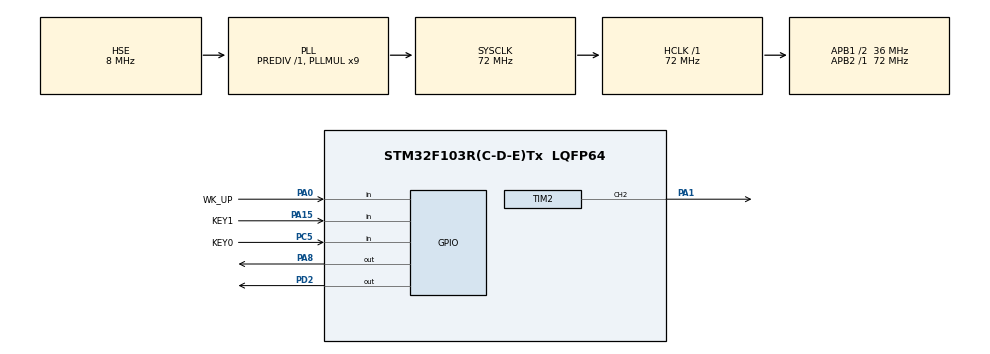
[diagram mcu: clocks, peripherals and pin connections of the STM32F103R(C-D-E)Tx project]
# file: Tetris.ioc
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Mcu.Family=STM32F1
Mcu.Name=STM32F103R(C-D-E)Tx
Mcu.Package=LQFP64
NVIC.PriorityGroup=NVIC_PRIORITYGROUP_4
PA0-WKUP.GPIO_Label=WK_UP
PA0-WKUP.GPIO_PuPd=GPIO_PULLDOWN
PA0-WKUP.Signal=GPIO_Input
PA1.GPIO_ModeDefaultPP=GPIO_MODE_AF_PP
PA1.GPIO_Speed=GPIO_SPEED_FREQ_LOW
PA1.Signal=S_TIM2_CH2
PA13.Mode=Serial_Wire
PA13.Signal=SYS_JTMS-SWDIO
PA14.Mode=Serial_Wire
PA14.Signal=SYS_JTCK-SWCLK
PA15.GPIO_Label=KEY1
PA15.GPIO_PuPd=GPIO_PULLUP
PA15.Signal=GPIO_Input
PA8.Signal=GPIO_Output
PC5.GPIO_Label=KEY0
PC5.GPIO_PuPd=GPIO_PULLUP
PC5.Signal=GPIO_Input
PD0-OSC_IN.Mode=HSE-External-Oscillator
PD0-OSC_IN.Signal=RCC_OSC_IN
PD1-OSC_OUT.Mode=HSE-External-Oscillator
PD1-OSC_OUT.Signal=RCC_OSC_OUT
PD2.Signal=GPIO_Output
ProjectManager.HeapSize=0x200
ProjectManager.StackSize=0x400
ProjectManager.TargetToolchain=STM32CubeIDE
RCC.AHBFreq_Value=72000000
RCC.APB1CLKDivider=RCC_HCLK_DIV2
RCC.APB1Freq_Value=36000000
RCC.APB1TimFreq_Value=72000000
RCC.APB2Freq_Value=72000000
RCC.APB2TimFreq_Value=72000000
RCC.HCLKFreq_Value=72000000
RCC.PLLMUL=RCC_PLL_MUL9
RCC.PLLSourceVirtual=RCC_PLLSOURCE_HSE
RCC.SYSCLKFreq_VALUE=72000000
RCC.SYSCLKSource=RCC_SYSCLKSOURCE_PLLCLK
RCC.USBFreq_Value=72000000
SH.S_TIM2_CH2.0=TIM2_CH2,PWM Generation2 CH2
TIM2.Channel-PWM\ Generation2\ CH2=TIM_CHANNEL_2
TIM2.Period=999
TIM2.Prescaler=71
board=custom

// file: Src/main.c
/* USER CODE BEGIN Header */
/**
  ******************************************************************************
  * @file           : main.c
  * @brief          : Main program body
  ******************************************************************************
  * @attention
  *
  * <h2><center>&copy; Copyright (c) 2019 STMicroelectronics.
  * All rights reserved.</center></h2>
  *
  * This software component is licensed by ST under BSD 3-Clause license,
  * the "License"; You may not use this file except in compliance with the
  * License. You may obtain a copy of the License at:
  *                        opensource.org/licenses/BSD-3-Clause
  *
  ******************************************************************************
  */
/* USER CODE END Header */

#include "main.h"

/* USER CODE BEGIN Includes */
#include "lcd.h"
#include "string.h"
#include "stdio.h"
#include "ui.h"

/* USER CODE END Includes */

TIM_HandleTypeDef htim2;

/* USER CODE BEGIN PV */
extern uint32_t uwTick;
extern const unsigned char JPGBUFF[];
// extern unsigned char JPGBUFF1[];
// extern unsigned char JPGBUFF2[];
// extern unsigned char JPGBUFF3[];
// extern unsigned char JPGBUFF4[];
/* USER CODE END PV */

void SystemClock_Config(void);
static void MX_GPIO_Init(void);
static void MX_TIM2_Init(void);

int main(void)
{

  /* MCU Configuration--------------------------------------------------------*/

  /* Reset of all peripherals, Initializes the Flash interface and the Systick. */
  HAL_Init();

  /* USER CODE BEGIN Init */
  LCD_Init();
  /* USER CODE END Init */

  /* Configure the system clock */
  SystemClock_Config();

  /* Initialize all configured peripherals */
  MX_GPIO_Init();
  MX_TIM2_Init();
  /* USER CODE BEGIN 2 */

  // LCD_Clear(WHITE);
  // POINT_COLOR = RED;
  // LCD_ShowString(30, 60, 200, 24, 24, (uint8_t*) "Tetris Welcome!");
  // POINT_COLOR = BLACK;
	// LCD_ShowString(30, 160, 200, 16, 16, (uint8_t*) "Press any key to start.");
  // // play_music();
  // while(1){
  //   HAL_Delay(21);
  //   if (HAL_GPIO_ReadPin(KEY1_GPIO_Port, KEY1_Pin) != GPIO_PIN_SET) {break;}
  //   if (HAL_GPIO_ReadPin(KEY0_GPIO_Port, KEY0_Pin) != GPIO_PIN_SET) {break;}
  //   if (HAL_GPIO_ReadPin(WK_UP_GPIO_Port, WK_UP_Pin) != GPIO_PIN_RESET) {break;}
  // }
  // LCD_Clear(WHITE);
  // game_reset();
  /* USER CODE END 2 */

  /* Infinite loop */
  while (1)
  {

    /* USER CODE BEGIN 3 */
	  POINT_COLOR=0xf100;//画笔颜色
    LCD_ShowString(30, 100, 240, 24, 24, "This is a test for JPG Decode!");
    HAL_Delay(1000);
    while (1)
    {
		LoadJpegFile(JPGBUFF);
    HAL_Delay(1800);HAL_Delay(1800);
		// LoadJpegFile(JPGBUFF1);
		// HAL_Delay(1800);HAL_Delay(1800);
		// LoadJpegFile(JPGBUFF2);
		// HAL_Delay(1800);HAL_Delay(1800);
		// LoadJpegFile(JPGBUFF3);
		// HAL_Delay(1800);HAL_Delay(1800);
		//TFT_CLEAR(0,0,240,320);//清屏
		// LoadJpegFile(JPGBUFF4);
		// HAL_Delay(1800);HAL_Delay(1800);
    }

    // if(uwTick - button_task_stamp >= button_update_interval){
		// 	button_task_stamp = uwTick;
		// 	button_update();
		// }
		// if(uwTick - fall_task_stamp >= fall_down_interval){
		// 	fall_task_stamp = uwTick;
		// 	grid_fall_down();
		// }

  }
  /* USER CODE END 3 */
}

void SystemClock_Config(void)
{
  RCC_OscInitTypeDef RCC_OscInitStruct = {0};
  RCC_ClkInitTypeDef RCC_ClkInitStruct = {0};

  /** Initializes the CPU, AHB and APB busses clocks
  */
  RCC_OscInitStruct.OscillatorType = RCC_OSCILLATORTYPE_HSE;
  RCC_OscInitStruct.HSEState = RCC_HSE_ON;
  RCC_OscInitStruct.HSEPredivValue = RCC_HSE_PREDIV_DIV1;
  RCC_OscInitStruct.HSIState = RCC_HSI_ON;
  RCC_OscInitStruct.PLL.PLLState = RCC_PLL_ON;
  RCC_OscInitStruct.PLL.PLLSource = RCC_PLLSOURCE_HSE;
  RCC_OscInitStruct.PLL.PLLMUL = RCC_PLL_MUL9;
  if (HAL_RCC_OscConfig(&RCC_OscInitStruct) != HAL_OK)
  {
    Error_Handler();
  }
  /** Initializes the CPU, AHB and APB busses clocks
  */
  RCC_ClkInitStruct.ClockType = RCC_CLOCKTYPE_HCLK|RCC_CLOCKTYPE_SYSCLK
                              |RCC_CLOCKTYPE_PCLK1|RCC_CLOCKTYPE_PCLK2;
  RCC_ClkInitStruct.SYSCLKSource = RCC_SYSCLKSOURCE_PLLCLK;
  RCC_ClkInitStruct.AHBCLKDivider = RCC_SYSCLK_DIV1;
  RCC_ClkInitStruct.APB1CLKDivider = RCC_HCLK_DIV2;
  RCC_ClkInitStruct.APB2CLKDivider = RCC_HCLK_DIV1;

  if (HAL_RCC_ClockConfig(&RCC_ClkInitStruct, FLASH_LATENCY_2) != HAL_OK)
  {
    Error_Handler();
  }
}

static void MX_TIM2_Init(void)
{

  TIM_MasterConfigTypeDef sMasterConfig = {0};
  TIM_OC_InitTypeDef sConfigOC = {0};

  htim2.Instance = TIM2;
  htim2.Init.Prescaler = 71;
  htim2.Init.CounterMode = TIM_COUNTERMODE_UP;
  htim2.Init.Period = 999;
  htim2.Init.ClockDivision = TIM_CLOCKDIVISION_DIV1;
  htim2.Init.AutoReloadPreload = TIM_AUTORELOAD_PRELOAD_DISABLE;
  if (HAL_TIM_PWM_Init(&htim2) != HAL_OK)
  {
    Error_Handler();
  }
  sMasterConfig.MasterOutputTrigger = TIM_TRGO_RESET;
  sMasterConfig.MasterSlaveMode = TIM_MASTERSLAVEMODE_DISABLE;
  if (HAL_TIMEx_MasterConfigSynchronization(&htim2, &sMasterConfig) != HAL_OK)
  {
    Error_Handler();
  }
  sConfigOC.OCMode = TIM_OCMODE_PWM1;
  sConfigOC.Pulse = 0;
  sConfigOC.OCPolarity = TIM_OCPOLARITY_HIGH;
  sConfigOC.OCFastMode = TIM_OCFAST_DISABLE;
  if (HAL_TIM_PWM_ConfigChannel(&htim2, &sConfigOC, TIM_CHANNEL_2) != HAL_OK)
  {
    Error_Handler();
  }
  HAL_TIM_MspPostInit(&htim2);

}

static void MX_GPIO_Init(void)
{
  GPIO_InitTypeDef GPIO_InitStruct = {0};

  /* GPIO Ports Clock Enable */
  __HAL_RCC_GPIOD_CLK_ENABLE();
  __HAL_RCC_GPIOA_CLK_ENABLE();
  __HAL_RCC_GPIOC_CLK_ENABLE();

  /*Configure GPIO pin Output Level */
  HAL_GPIO_WritePin(GPIOA, GPIO_PIN_8, GPIO_PIN_RESET);

  /*Configure GPIO pin Output Level */
  HAL_GPIO_WritePin(GPIOD, GPIO_PIN_2, GPIO_PIN_RESET);

  /*Configure GPIO pin : WK_UP_Pin */
  GPIO_InitStruct.Pin = WK_UP_Pin;
  GPIO_InitStruct.Mode = GPIO_MODE_INPUT;
  GPIO_InitStruct.Pull = GPIO_PULLDOWN;
  HAL_GPIO_Init(WK_UP_GPIO_Port, &GPIO_InitStruct);

  /*Configure GPIO pin : KEY0_Pin */
  GPIO_InitStruct.Pin = KEY0_Pin;
  GPIO_InitStruct.Mode = GPIO_MODE_INPUT;
  GPIO_InitStruct.Pull = GPIO_PULLUP;
  HAL_GPIO_Init(KEY0_GPIO_Port, &GPIO_InitStruct);

  /*Configure GPIO pin : PA8 */
  GPIO_InitStruct.Pin = GPIO_PIN_8;
  GPIO_InitStruct.Mode = GPIO_MODE_OUTPUT_PP;
  GPIO_InitStruct.Pull = GPIO_NOPULL;
  GPIO_InitStruct.Speed = GPIO_SPEED_FREQ_LOW;
  HAL_GPIO_Init(GPIOA, &GPIO_InitStruct);

  /*Configure GPIO pin : KEY1_Pin */
  GPIO_InitStruct.Pin = KEY1_Pin;
  GPIO_InitStruct.Mode = GPIO_MODE_INPUT;
  GPIO_InitStruct.Pull = GPIO_PULLUP;
  HAL_GPIO_Init(KEY1_GPIO_Port, &GPIO_InitStruct);

  /*Configure GPIO pin : PD2 */
  GPIO_InitStruct.Pin = GPIO_PIN_2;
  GPIO_InitStruct.Mode = GPIO_MODE_OUTPUT_PP;
  GPIO_InitStruct.Pull = GPIO_NOPULL;
  GPIO_InitStruct.Speed = GPIO_SPEED_FREQ_LOW;
  HAL_GPIO_Init(GPIOD, &GPIO_InitStruct);

}

void Error_Handler(void)
{
}

/************************ (C) COPYRIGHT STMicroelectronics *****END OF FILE****/
